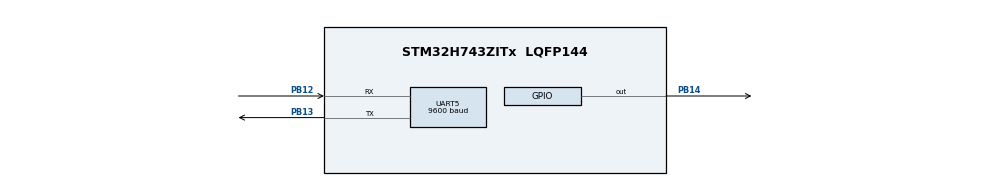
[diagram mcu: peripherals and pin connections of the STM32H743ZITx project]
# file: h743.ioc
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Mcu.Family=STM32H7
Mcu.Name=STM32H743ZITx
Mcu.Package=LQFP144
NVIC.PriorityGroup=NVIC_PRIORITYGROUP_4
NVIC.UART5_IRQn=true\:0\:0\:false\:false\:true\:true\:true\:true
PB12.Mode=Asynchronous
PB12.Signal=UART5_RX
PB13.Mode=Asynchronous
PB13.Signal=UART5_TX
PB14.Signal=GPIO_Output
PH0-OSC_IN\ (PH0).Mode=HSE-External-Oscillator
PH0-OSC_IN\ (PH0).Signal=RCC_OSC_IN
PH1-OSC_OUT\ (PH1).Mode=HSE-External-Oscillator
PH1-OSC_OUT\ (PH1).Signal=RCC_OSC_OUT
ProjectManager.HeapSize=0x200
ProjectManager.StackSize=0x400
ProjectManager.TargetToolchain=STM32CubeIDE
RCC.ADCFreq_Value=129000000
RCC.APB1Freq_Value=40000000
RCC.APB2Freq_Value=80000000
RCC.APB3Freq_Value=80000000
RCC.APB4Freq_Value=80000000
RCC.CortexFreq_Value=80000000
RCC.D2PPRE1=RCC_APB1_DIV2
RCC.DIVM1=4
RCC.DIVN1=10
RCC.HCLKFreq_Value=80000000
RCC.PLL2FRACN=0
RCC.PLL3FRACN=0
RCC.PLLFRACN=0
RCC.SYSCLKFreq_VALUE=80000000
RCC.SYSCLKSource=RCC_SYSCLKSOURCE_PLLCLK
RCC.USBFreq_Value=80000000
UART5.BaudRate=9600
board=custom

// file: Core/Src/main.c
/* USER CODE BEGIN Header */
/**
  ******************************************************************************
  * @file           : main.c
  * @brief          : Main program body
  ******************************************************************************
  * @attention
  *
  * Copyright (c) 2024 STMicroelectronics.
  * All rights reserved.
  *
  * This software is licensed under terms that can be found in the LICENSE file
  * in the root directory of this software component.
  * If no LICENSE file comes with this software, it is provided AS-IS.
  *
  ******************************************************************************
  */
/* USER CODE END Header */
#include "main.h"

/* USER CODE BEGIN Includes */
#include "modbusSlave.h"
/* USER CODE END Includes */

UART_HandleTypeDef huart5;

void SystemClock_Config(void);
static void MX_GPIO_Init(void);
static void MX_UART5_Init(void);

/* USER CODE BEGIN 0 */
uint8_t RxData[256];
uint8_t TxData[256];

void HAL_UARTEx_RxEventCallback(UART_HandleTypeDef *huart, uint16_t Size)
{
	if (RxData[0] == SLAVE_ID)
	{
		switch (RxData[1]){
		case 0x03:
			readHoldingRegs();
			break;
		case 0x04:
			readInputRegs();
			break;
		case 0x01:
			readCoils();
			break;
		case 0x02:
			readInputs();
			break;
		case 0x06:
			writeSingleReg();
			break;
		case 0x10:
			writeHoldingRegs();
			break;
		case 0x05:
			writeSingleCoil();
			break;
		case 0x0F:
			writeMultiCoils();
			break;
		default:
			modbusException(ILLEGAL_FUNCTION);
			break;
		}
	}

	HAL_UARTEx_ReceiveToIdle_IT(&huart5, RxData, 256);
}
/* USER CODE END 0 */

int main(void)
{

  /* MCU Configuration--------------------------------------------------------*/

  /* Reset of all peripherals, Initializes the Flash interface and the Systick. */
  HAL_Init();

  /* Configure the system clock */
  SystemClock_Config();

  /* Initialize all configured peripherals */
  MX_GPIO_Init();
  MX_UART5_Init();
  /* USER CODE BEGIN 2 */

  HAL_UARTEx_ReceiveToIdle_IT(&huart5, RxData, 256);
  /* USER CODE END 2 */

  /* Infinite loop */
  while (1)
  {

    /* USER CODE BEGIN 3 */
//	  HAL_GPIO_TogglePin(GPIOB, GPIO_PIN_14);
//	  	  HAL_Delay(500);
  }
  /* USER CODE END 3 */
}

void SystemClock_Config(void)
{
  RCC_OscInitTypeDef RCC_OscInitStruct = {0};
  RCC_ClkInitTypeDef RCC_ClkInitStruct = {0};

  /** Supply configuration update enable
  */
  HAL_PWREx_ConfigSupply(PWR_LDO_SUPPLY);

  /** Configure the main internal regulator output voltage
  */
  __HAL_PWR_VOLTAGESCALING_CONFIG(PWR_REGULATOR_VOLTAGE_SCALE3);

  while(!__HAL_PWR_GET_FLAG(PWR_FLAG_VOSRDY)) {}

  /** Initializes the RCC Oscillators according to the specified parameters
  * in the RCC_OscInitTypeDef structure.
  */
  RCC_OscInitStruct.OscillatorType = RCC_OSCILLATORTYPE_HSI;
  RCC_OscInitStruct.HSIState = RCC_HSI_DIV1;
  RCC_OscInitStruct.HSICalibrationValue = RCC_HSICALIBRATION_DEFAULT;
  RCC_OscInitStruct.PLL.PLLState = RCC_PLL_ON;
  RCC_OscInitStruct.PLL.PLLSource = RCC_PLLSOURCE_HSI;
  RCC_OscInitStruct.PLL.PLLM = 4;
  RCC_OscInitStruct.PLL.PLLN = 10;
  RCC_OscInitStruct.PLL.PLLP = 2;
  RCC_OscInitStruct.PLL.PLLQ = 2;
  RCC_OscInitStruct.PLL.PLLR = 2;
  RCC_OscInitStruct.PLL.PLLRGE = RCC_PLL1VCIRANGE_3;
  RCC_OscInitStruct.PLL.PLLVCOSEL = RCC_PLL1VCOMEDIUM;
  RCC_OscInitStruct.PLL.PLLFRACN = 0;
  if (HAL_RCC_OscConfig(&RCC_OscInitStruct) != HAL_OK)
  {
    Error_Handler();
  }

  /** Initializes the CPU, AHB and APB buses clocks
  */
  RCC_ClkInitStruct.ClockType = RCC_CLOCKTYPE_HCLK|RCC_CLOCKTYPE_SYSCLK
                              |RCC_CLOCKTYPE_PCLK1|RCC_CLOCKTYPE_PCLK2
                              |RCC_CLOCKTYPE_D3PCLK1|RCC_CLOCKTYPE_D1PCLK1;
  RCC_ClkInitStruct.SYSCLKSource = RCC_SYSCLKSOURCE_PLLCLK;
  RCC_ClkInitStruct.SYSCLKDivider = RCC_SYSCLK_DIV1;
  RCC_ClkInitStruct.AHBCLKDivider = RCC_HCLK_DIV1;
  RCC_ClkInitStruct.APB3CLKDivider = RCC_APB3_DIV1;
  RCC_ClkInitStruct.APB1CLKDivider = RCC_APB1_DIV2;
  RCC_ClkInitStruct.APB2CLKDivider = RCC_APB2_DIV1;
  RCC_ClkInitStruct.APB4CLKDivider = RCC_APB4_DIV1;

  if (HAL_RCC_ClockConfig(&RCC_ClkInitStruct, FLASH_LATENCY_1) != HAL_OK)
  {
    Error_Handler();
  }
}

static void MX_UART5_Init(void)
{

  huart5.Instance = UART5;
  huart5.Init.BaudRate = 9600;
  huart5.Init.WordLength = UART_WORDLENGTH_8B;
  huart5.Init.StopBits = UART_STOPBITS_1;
  huart5.Init.Parity = UART_PARITY_NONE;
  huart5.Init.Mode = UART_MODE_TX_RX;
  huart5.Init.HwFlowCtl = UART_HWCONTROL_NONE;
  huart5.Init.OverSampling = UART_OVERSAMPLING_16;
  huart5.Init.OneBitSampling = UART_ONE_BIT_SAMPLE_DISABLE;
  huart5.Init.ClockPrescaler = UART_PRESCALER_DIV1;
  huart5.AdvancedInit.AdvFeatureInit = UART_ADVFEATURE_NO_INIT;
  if (HAL_UART_Init(&huart5) != HAL_OK)
  {
    Error_Handler();
  }
  if (HAL_UARTEx_SetTxFifoThreshold(&huart5, UART_TXFIFO_THRESHOLD_1_8) != HAL_OK)
  {
    Error_Handler();
  }
  if (HAL_UARTEx_SetRxFifoThreshold(&huart5, UART_RXFIFO_THRESHOLD_1_8) != HAL_OK)
  {
    Error_Handler();
  }
  if (HAL_UARTEx_DisableFifoMode(&huart5) != HAL_OK)
  {
    Error_Handler();
  }

}

static void MX_GPIO_Init(void)
{
  GPIO_InitTypeDef GPIO_InitStruct = {0};

  /* GPIO Ports Clock Enable */
  __HAL_RCC_GPIOH_CLK_ENABLE();
  __HAL_RCC_GPIOB_CLK_ENABLE();

  /*Configure GPIO pin Output Level */
  HAL_GPIO_WritePin(GPIOB, GPIO_PIN_14, GPIO_PIN_RESET);

  /*Configure GPIO pin : PB14 */
  GPIO_InitStruct.Pin = GPIO_PIN_14;
  GPIO_InitStruct.Mode = GPIO_MODE_OUTPUT_PP;
  GPIO_InitStruct.Pull = GPIO_NOPULL;
  GPIO_InitStruct.Speed = GPIO_SPEED_FREQ_LOW;
  HAL_GPIO_Init(GPIOB, &GPIO_InitStruct);

}

void Error_Handler(void)
{
  __disable_irq();
  while (1)
  {
  }
}
